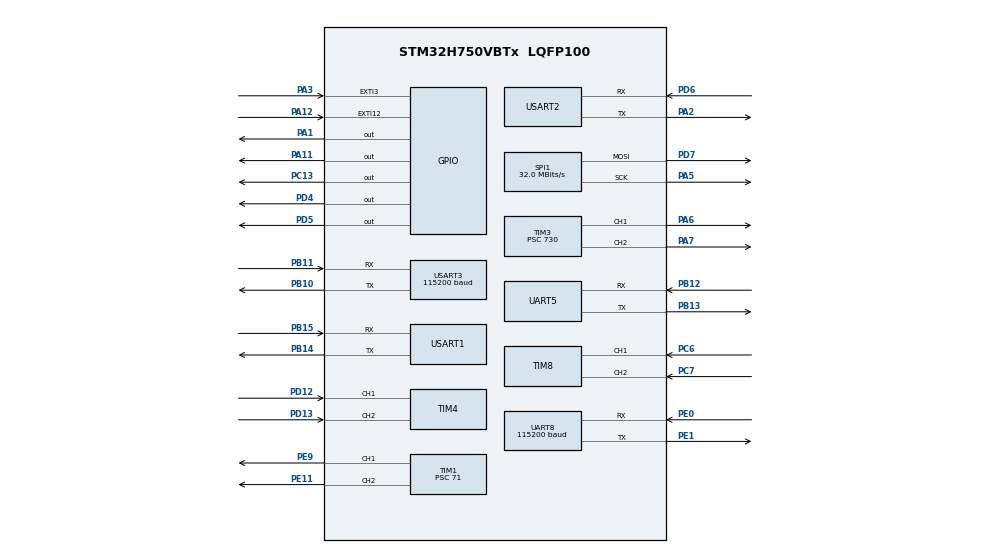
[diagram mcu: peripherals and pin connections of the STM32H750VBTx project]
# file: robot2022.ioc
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Dma.Request0=UART5_RX
Dma.Request1=UART5_TX
Dma.Request2=USART3_RX
Dma.Request3=USART3_TX
Dma.UART5_RX.0.Direction=DMA_PERIPH_TO_MEMORY
Dma.UART5_RX.0.EventEnable=DISABLE
Dma.UART5_RX.0.FIFOMode=DMA_FIFOMODE_DISABLE
Dma.UART5_RX.0.Instance=DMA1_Stream3
Dma.UART5_RX.0.MemDataAlignment=DMA_MDATAALIGN_BYTE
Dma.UART5_RX.0.MemInc=DMA_MINC_ENABLE
Dma.UART5_RX.0.Mode=DMA_NORMAL
Dma.UART5_RX.0.PeriphDataAlignment=DMA_PDATAALIGN_BYTE
Dma.UART5_RX.0.PeriphInc=DMA_PINC_DISABLE
Dma.UART5_RX.0.Polarity=HAL_DMAMUX_REQ_GEN_RISING
Dma.UART5_RX.0.Priority=DMA_PRIORITY_LOW
Dma.UART5_RX.0.RequestNumber=1
Dma.UART5_RX.0.SignalID=NONE
Dma.UART5_RX.0.SyncEnable=DISABLE
Dma.UART5_RX.0.SyncPolarity=HAL_DMAMUX_SYNC_NO_EVENT
Dma.UART5_RX.0.SyncRequestNumber=1
Dma.UART5_RX.0.SyncSignalID=NONE
Dma.UART5_TX.1.Direction=DMA_MEMORY_TO_PERIPH
Dma.UART5_TX.1.EventEnable=DISABLE
Dma.UART5_TX.1.FIFOMode=DMA_FIFOMODE_DISABLE
Dma.UART5_TX.1.Instance=DMA1_Stream4
Dma.UART5_TX.1.MemDataAlignment=DMA_MDATAALIGN_BYTE
Dma.UART5_TX.1.MemInc=DMA_MINC_ENABLE
Dma.UART5_TX.1.Mode=DMA_NORMAL
Dma.UART5_TX.1.PeriphDataAlignment=DMA_PDATAALIGN_BYTE
Dma.UART5_TX.1.PeriphInc=DMA_PINC_DISABLE
Dma.UART5_TX.1.Polarity=HAL_DMAMUX_REQ_GEN_RISING
Dma.UART5_TX.1.Priority=DMA_PRIORITY_LOW
Dma.UART5_TX.1.RequestNumber=1
Dma.UART5_TX.1.SignalID=NONE
Dma.UART5_TX.1.SyncEnable=DISABLE
Dma.UART5_TX.1.SyncPolarity=HAL_DMAMUX_SYNC_NO_EVENT
Dma.UART5_TX.1.SyncRequestNumber=1
Dma.UART5_TX.1.SyncSignalID=NONE
Dma.USART3_RX.2.Direction=DMA_PERIPH_TO_MEMORY
Dma.USART3_RX.2.EventEnable=DISABLE
Dma.USART3_RX.2.FIFOMode=DMA_FIFOMODE_DISABLE
Dma.USART3_RX.2.Instance=DMA1_Stream0
Dma.USART3_RX.2.MemDataAlignment=DMA_MDATAALIGN_BYTE
Dma.USART3_RX.2.MemInc=DMA_MINC_ENABLE
Dma.USART3_RX.2.Mode=DMA_NORMAL
Dma.USART3_RX.2.PeriphDataAlignment=DMA_PDATAALIGN_BYTE
Dma.USART3_RX.2.PeriphInc=DMA_PINC_DISABLE
Dma.USART3_RX.2.Polarity=HAL_DMAMUX_REQ_GEN_RISING
Dma.USART3_RX.2.Priority=DMA_PRIORITY_HIGH
Dma.USART3_RX.2.RequestNumber=1
Dma.USART3_RX.2.SignalID=NONE
Dma.USART3_RX.2.SyncEnable=DISABLE
Dma.USART3_RX.2.SyncPolarity=HAL_DMAMUX_SYNC_NO_EVENT
Dma.USART3_RX.2.SyncRequestNumber=1
Dma.USART3_RX.2.SyncSignalID=NONE
Dma.USART3_TX.3.Direction=DMA_MEMORY_TO_PERIPH
Dma.USART3_TX.3.EventEnable=DISABLE
Dma.USART3_TX.3.FIFOMode=DMA_FIFOMODE_DISABLE
Dma.USART3_TX.3.Instance=DMA1_Stream1
Dma.USART3_TX.3.MemDataAlignment=DMA_MDATAALIGN_BYTE
Dma.USART3_TX.3.MemInc=DMA_MINC_ENABLE
Dma.USART3_TX.3.Mode=DMA_NORMAL
Dma.USART3_TX.3.PeriphDataAlignment=DMA_PDATAALIGN_BYTE
Dma.USART3_TX.3.PeriphInc=DMA_PINC_DISABLE
Dma.USART3_TX.3.Polarity=HAL_DMAMUX_REQ_GEN_RISING
Dma.USART3_TX.3.Priority=DMA_PRIORITY_HIGH
Dma.USART3_TX.3.RequestNumber=1
Dma.USART3_TX.3.SignalID=NONE
Dma.USART3_TX.3.SyncEnable=DISABLE
Dma.USART3_TX.3.SyncPolarity=HAL_DMAMUX_SYNC_NO_EVENT
Dma.USART3_TX.3.SyncRequestNumber=1
Dma.USART3_TX.3.SyncSignalID=NONE
Mcu.Family=STM32H7
Mcu.Name=STM32H750VBTx
Mcu.Package=LQFP100
NVIC.DMA1_Stream0_IRQn=true\:1\:0\:true\:false\:true\:false\:true\:true
NVIC.DMA1_Stream1_IRQn=true\:1\:0\:true\:false\:true\:false\:true\:true
NVIC.DMA1_Stream3_IRQn=true\:1\:1\:true\:false\:true\:false\:true\:true
NVIC.DMA1_Stream4_IRQn=true\:1\:1\:true\:false\:true\:false\:true\:true
NVIC.EXTI15_10_IRQn=true\:3\:2\:true\:false\:true\:true\:true\:true
NVIC.PriorityGroup=NVIC_PRIORITYGROUP_2
NVIC.TIM2_IRQn=true\:3\:2\:true\:false\:true\:true\:true\:true
NVIC.TIM3_IRQn=true\:3\:1\:true\:false\:true\:true\:true\:true
NVIC.TIM4_IRQn=true\:3\:0\:true\:false\:true\:true\:true\:true
NVIC.UART5_IRQn=true\:1\:1\:true\:false\:true\:true\:true\:true
NVIC.UART8_IRQn=true\:0\:0\:false\:false\:true\:true\:true\:true
NVIC.USART2_IRQn=true\:0\:0\:false\:false\:true\:true\:true\:true
NVIC.USART3_IRQn=true\:1\:0\:true\:false\:true\:true\:true\:true
PA1.Signal=GPIO_Output
PA11.Signal=GPIO_Output
PA12.Signal=GPXTI12
PA13\ (JTMS/SWDIO).Mode=Serial_Wire
PA13\ (JTMS/SWDIO).Signal=DEBUG_JTMS-SWDIO
PA14\ (JTCK/SWCLK).Mode=Serial_Wire
PA14\ (JTCK/SWCLK).Signal=DEBUG_JTCK-SWCLK
PA2.GPIO_Speed=GPIO_SPEED_FREQ_VERY_HIGH
PA2.Mode=Asynchronous
PA2.Signal=USART2_TX
PA3.Signal=GPXTI3
PA5.Mode=TX_Only_Simplex_Unidirect_Master
PA5.Signal=SPI1_SCK
PA6.Signal=S_TIM3_CH1
PA7.Signal=S_TIM3_CH2
PB10.GPIO_Speed=GPIO_SPEED_FREQ_VERY_HIGH
PB10.Mode=Asynchronous
PB10.Signal=USART3_TX
PB11.GPIO_Speed=GPIO_SPEED_FREQ_VERY_HIGH
PB11.Mode=Asynchronous
PB11.Signal=USART3_RX
PB12.Mode=Asynchronous
PB12.Signal=UART5_RX
PB13.Mode=Asynchronous
PB13.Signal=UART5_TX
PB14.GPIO_Speed=GPIO_SPEED_FREQ_VERY_HIGH
PB14.Mode=Asynchronous
PB14.Signal=USART1_TX
PB15.GPIO_Speed=GPIO_SPEED_FREQ_VERY_HIGH
PB15.Mode=Asynchronous
PB15.Signal=USART1_RX
PC13.Signal=GPIO_Output
PC6.Signal=S_TIM8_CH1
PC7.Signal=S_TIM8_CH2
PD12.Signal=S_TIM4_CH1
PD13.Signal=S_TIM4_CH2
PD4.Signal=GPIO_Output
PD5.Signal=GPIO_Output
PD6.GPIO_ModeDefaultPP=GPIO_MODE_AF_PP
PD6.GPIO_Speed=GPIO_SPEED_FREQ_VERY_HIGH
PD6.Mode=Asynchronous
PD6.Signal=USART2_RX
PD7.Mode=TX_Only_Simplex_Unidirect_Master
PD7.Signal=SPI1_MOSI
PE0.GPIO_Speed=GPIO_SPEED_FREQ_VERY_HIGH
PE0.Mode=Asynchronous
PE0.Signal=UART8_RX
PE1.GPIO_Speed=GPIO_SPEED_FREQ_VERY_HIGH
PE1.Mode=Asynchronous
PE1.Signal=UART8_TX
PE11.GPIO_Speed=GPIO_SPEED_FREQ_MEDIUM
PE11.Signal=S_TIM1_CH2
PE9.GPIO_Speed=GPIO_SPEED_FREQ_MEDIUM
PE9.Signal=S_TIM1_CH1
PH0-OSC_IN\ (PH0).Mode=HSE-External-Oscillator
PH0-OSC_IN\ (PH0).Signal=RCC_OSC_IN
PH1-OSC_OUT\ (PH1).Mode=HSE-External-Oscillator
PH1-OSC_OUT\ (PH1).Signal=RCC_OSC_OUT
ProjectManager.HeapSize=0x200
ProjectManager.StackSize=0x400
ProjectManager.TargetToolchain=MDK-ARM V5.32
RCC.ADCFreq_Value=480000000
RCC.APB1Freq_Value=48000000
RCC.APB2Freq_Value=48000000
RCC.APB3Freq_Value=48000000
RCC.APB4Freq_Value=48000000
RCC.CortexFreq_Value=96000000
RCC.DIVM1=25
RCC.DIVM2=5
RCC.DIVM3=5
RCC.DIVN1=192
RCC.DIVN2=192
RCC.DIVN3=192
RCC.HCLKFreq_Value=48000000
RCC.HPRE=RCC_HCLK_DIV2
RCC.HSE_VALUE=25000000
RCC.PLLSourceVirtual=RCC_PLLSOURCE_HSE
RCC.SPI123CLockSelection=RCC_SPI123CLKSOURCE_CLKP
RCC.SYSCLKFreq_VALUE=96000000
RCC.SYSCLKSource=RCC_SYSCLKSOURCE_PLLCLK
RCC.USBFreq_Value=96000000
SH.S_TIM1_CH1.0=TIM1_CH1,PWM Generation1 CH1
SH.S_TIM1_CH2.0=TIM1_CH2,PWM Generation2 CH2
SH.S_TIM3_CH1.0=TIM3_CH1,PWM Generation1 CH1
SH.S_TIM3_CH2.0=TIM3_CH2,PWM Generation2 CH2
SH.S_TIM4_CH1.0=TIM4_CH1,Encoder_Interface
SH.S_TIM4_CH2.0=TIM4_CH2,Encoder_Interface
SH.S_TIM8_CH1.0=TIM8_CH1,Encoder_Interface
SH.S_TIM8_CH2.0=TIM8_CH2,Encoder_Interface
SPI1.CalculateBaudRate=32.0 MBits/s
SPI1.DataSize=SPI_DATASIZE_8BIT
SPI1.Direction=SPI_DIRECTION_2LINES_TXONLY
SPI1.Mode=SPI_MODE_MASTER
SPI1.VirtualType=VM_MASTER
TIM1.AutoReloadPreload=TIM_AUTORELOAD_PRELOAD_ENABLE
TIM1.Channel-PWM\ Generation1\ CH1=TIM_CHANNEL_1
TIM1.Channel-PWM\ Generation2\ CH2=TIM_CHANNEL_2
TIM1.OCPolarity_1=TIM_OCPOLARITY_HIGH
TIM1.OCPolarity_2=TIM_OCPOLARITY_HIGH
TIM1.Period=32
TIM1.Prescaler=71
TIM2.Period=99
TIM2.Prescaler=23999
TIM3.Channel-PWM\ Generation1\ CH1=TIM_CHANNEL_1
TIM3.Channel-PWM\ Generation2\ CH2=TIM_CHANNEL_2
TIM3.Period=199
TIM3.Prescaler=730
UART8.BaudRate=115200
USART1.VirtualMode-Asynchronous=VM_ASYNC
USART2.VirtualMode-Asynchronous=VM_ASYNC
USART3.BaudRate=115200
USART3.VirtualMode-Asynchronous=VM_ASYNC
VP_TIM1_VS_ClockSourceINT.Mode=Internal
VP_TIM2_VS_ClockSourceINT.Mode=Internal
VP_TIM3_VS_ClockSourceINT.Mode=Internal
board=custom

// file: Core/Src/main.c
/* USER CODE BEGIN Header */
/**
  ******************************************************************************
  * @file           : main.c
  * @brief          : Main program body
  ******************************************************************************
  * @attention
  *
  * Copyright (c) 2022 STMicroelectronics.
  * All rights reserved.
  *
  * This software is licensed under terms that can be found in the LICENSE file
  * in the root directory of this software component.
  * If no LICENSE file comes with this software, it is provided AS-IS.
  *
  ******************************************************************************
  */
/* USER CODE END Header */
#include "main.h"
#include "dma.h"
#include "spi.h"
#include "tim.h"
#include "usart.h"
#include "gpio.h"

/* USER CODE BEGIN Includes */
#include "UserFSM.h"
#include "UserMain.h"
/* USER CODE END Includes */

void SystemClock_Config(void);
void PeriphCommonClock_Config(void);

int main(void)
{

  /* MCU Configuration--------------------------------------------------------*/

  /* Reset of all peripherals, Initializes the Flash interface and the Systick. */
  HAL_Init();

  /* USER CODE BEGIN Init */
 /* USER CODE BEGIN Init */
//	uint8_t Senbuff[] = "\r\n**** Serial Output Message by DMA ***\r\n   UART DMA Test \r\n   Zxiaoxuan";  //定义数据发送数组
  /* USER CODE END Init */

  /* Configure the system clock */
  SystemClock_Config();

/* Configure the peripherals common clocks */
  PeriphCommonClock_Config();

  /* Initialize all configured peripherals */
  MX_GPIO_Init();
  MX_TIM1_Init();
  MX_UART8_Init();
  MX_USART1_UART_Init();
  MX_DMA_Init();
  MX_USART3_UART_Init();
  MX_TIM2_Init();
  MX_TIM3_Init();
  MX_TIM4_Init();
  MX_UART5_Init();
  MX_SPI1_Init();
  MX_TIM8_Init();
  MX_USART2_UART_Init();
  /* USER CODE BEGIN 2 */
  UserInit();

  /* USER CODE END 2 */

  /* Infinite loop */
  while (1)
  {

    /* USER CODE BEGIN 3 */
//		TurnBack();
//		SetMotorSpeed(LMotor,20);
//		SetMotorSpeed(RMotor,20);
		NormalLineSpeedPatrol();
//		HAL_Delay(1000);
//		LowSpeedLinePatrol();
//		GoBrige();
//    NormalLineSpeedPatrol();
//		CirclePatrol();

  }
  /* USER CODE END 3 */
}

void SystemClock_Config(void)
{
  RCC_OscInitTypeDef RCC_OscInitStruct = {0};
  RCC_ClkInitTypeDef RCC_ClkInitStruct = {0};

  /** Supply configuration update enable
  */
  HAL_PWREx_ConfigSupply(PWR_LDO_SUPPLY);
  /** Configure the main internal regulator output voltage
  */
  __HAL_PWR_VOLTAGESCALING_CONFIG(PWR_REGULATOR_VOLTAGE_SCALE3);

  while(!__HAL_PWR_GET_FLAG(PWR_FLAG_VOSRDY)) {}
  /** Initializes the RCC Oscillators according to the specified parameters
  * in the RCC_OscInitTypeDef structure.
  */
  RCC_OscInitStruct.OscillatorType = RCC_OSCILLATORTYPE_HSI|RCC_OSCILLATORTYPE_HSE;
  RCC_OscInitStruct.HSEState = RCC_HSE_ON;
  RCC_OscInitStruct.HSIState = RCC_HSI_DIV1;
  RCC_OscInitStruct.HSICalibrationValue = RCC_HSICALIBRATION_DEFAULT;
  RCC_OscInitStruct.PLL.PLLState = RCC_PLL_ON;
  RCC_OscInitStruct.PLL.PLLSource = RCC_PLLSOURCE_HSE;
  RCC_OscInitStruct.PLL.PLLM = 25;
  RCC_OscInitStruct.PLL.PLLN = 192;
  RCC_OscInitStruct.PLL.PLLP = 2;
  RCC_OscInitStruct.PLL.PLLQ = 2;
  RCC_OscInitStruct.PLL.PLLR = 2;
  RCC_OscInitStruct.PLL.PLLRGE = RCC_PLL1VCIRANGE_0;
  RCC_OscInitStruct.PLL.PLLVCOSEL = RCC_PLL1VCOWIDE;
  RCC_OscInitStruct.PLL.PLLFRACN = 0;
  if (HAL_RCC_OscConfig(&RCC_OscInitStruct) != HAL_OK)
  {
    Error_Handler();
  }
  /** Initializes the CPU, AHB and APB buses clocks
  */
  RCC_ClkInitStruct.ClockType = RCC_CLOCKTYPE_HCLK|RCC_CLOCKTYPE_SYSCLK
                              |RCC_CLOCKTYPE_PCLK1|RCC_CLOCKTYPE_PCLK2
                              |RCC_CLOCKTYPE_D3PCLK1|RCC_CLOCKTYPE_D1PCLK1;
  RCC_ClkInitStruct.SYSCLKSource = RCC_SYSCLKSOURCE_PLLCLK;
  RCC_ClkInitStruct.SYSCLKDivider = RCC_SYSCLK_DIV1;
  RCC_ClkInitStruct.AHBCLKDivider = RCC_HCLK_DIV2;
  RCC_ClkInitStruct.APB3CLKDivider = RCC_APB3_DIV1;
  RCC_ClkInitStruct.APB1CLKDivider = RCC_APB1_DIV1;
  RCC_ClkInitStruct.APB2CLKDivider = RCC_APB2_DIV1;
  RCC_ClkInitStruct.APB4CLKDivider = RCC_APB4_DIV1;

  if (HAL_RCC_ClockConfig(&RCC_ClkInitStruct, FLASH_LATENCY_1) != HAL_OK)
  {
    Error_Handler();
  }
}

void PeriphCommonClock_Config(void)
{
  RCC_PeriphCLKInitTypeDef PeriphClkInitStruct = {0};

  /** Initializes the peripherals clock
  */
  PeriphClkInitStruct.PeriphClockSelection = RCC_PERIPHCLK_CKPER;
  PeriphClkInitStruct.CkperClockSelection = RCC_CLKPSOURCE_HSI;
  if (HAL_RCCEx_PeriphCLKConfig(&PeriphClkInitStruct) != HAL_OK)
  {
    Error_Handler();
  }
}

void Error_Handler(void)
{
  /* USER CODE BEGIN Error_Handler_Debug */
  /* User can add his own implementation to report the HAL error return state */
  __disable_irq();
  while (1)
  {
				HAL_GPIO_WritePin(LED_GPIO_PORT, LED_GPIO_PIN, GPIO_PIN_SET); 		//之后可以改为蜂鸣器

  }
  /* USER CODE END Error_Handler_Debug */
}
